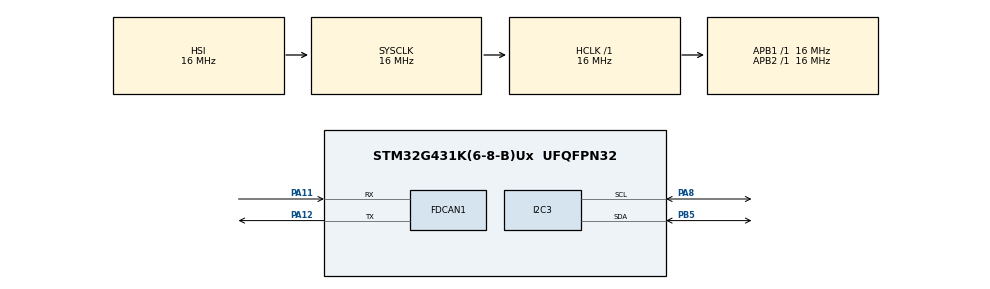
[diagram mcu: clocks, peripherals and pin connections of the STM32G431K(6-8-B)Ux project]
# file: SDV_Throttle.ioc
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FDCAN1.CalculateBaudRateNominal=500000
FDCAN1.CalculateTimeBitNominal=2000
FDCAN1.CalculateTimeQuantumNominal=125.0
FDCAN1.DataPrescaler=16
FDCAN1.DataTimeSeg1=14
FDCAN1.DataTimeSeg2=2
FDCAN1.NominalPrescaler=2
FDCAN1.NominalTimeSeg1=13
FREERTOS.Tasks01=defaultTask,24,128,StartDefaultTask,Default,NULL,Dynamic,NULL,NULL;canTask_tx,32,128,can_tx_task,Default,NULL,Dynamic,NULL,NULL;canTask_rx,33,128,can_rx_task,Default,NULL,Dynamic,NULL,NULL;canTask_panel,8,128,can_task_panel,Default,NULL,Dynamic,NULL,NULL;canTask_pot,8,128,can_task_pot,Default,NULL,Dynamic,NULL,NULL;canTask_lcd,8,128,can_task_lcd,Default,NULL,Dynamic,NULL,NULL
FREERTOS.configUSE_NEWLIB_REENTRANT=1
Mcu.Family=STM32G4
Mcu.Name=STM32G431K(6-8-B)Ux
Mcu.Package=UFQFPN32
NVIC.PriorityGroup=NVIC_PRIORITYGROUP_4
PA11.Mode=FDCAN_Activate
PA11.Signal=FDCAN1_RX
PA12.Mode=FDCAN_Activate
PA12.Signal=FDCAN1_TX
PA8.Mode=I2C
PA8.Signal=I2C3_SCL
PB5.Mode=I2C
PB5.Signal=I2C3_SDA
ProjectManager.HeapSize=0x200
ProjectManager.StackSize=0x400
ProjectManager.TargetToolchain=STM32CubeIDE
RCC.AHBFreq_Value=16000000
RCC.APB1Freq_Value=16000000
RCC.APB1TimFreq_Value=16000000
RCC.APB2Freq_Value=16000000
RCC.APB2TimFreq_Value=16000000
RCC.CortexFreq_Value=16000000
RCC.EXTERNAL_CLOCK_VALUE=12288000
RCC.HCLKFreq_Value=16000000
RCC.HSE_VALUE=8000000
RCC.HSI48_VALUE=48000000
RCC.HSI_VALUE=16000000
RCC.LSE_VALUE=32768
RCC.SYSCLKFreq_VALUE=16000000
RCC.USBFreq_Value=64000000
RCC.VCOOutputFreq_Value=128000000
VP_FREERTOS_VS_CMSIS_V2.Mode=CMSIS_V2
board=custom

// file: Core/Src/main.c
/* USER CODE BEGIN Header */
/**
  ******************************************************************************
  * @file           : main.c
  * @brief          : Main program body
  ******************************************************************************
  * @attention
  *
  * Copyright (c) 2022 STMicroelectronics.
  * All rights reserved.
  *
  * This software is licensed under terms that can be found in the LICENSE file
  * in the root directory of this software component.
  * If no LICENSE file comes with this software, it is provided AS-IS.
  *
  ******************************************************************************
  */
/* USER CODE END Header */
#include "main.h"
#include "cmsis_os.h"

FDCAN_HandleTypeDef hfdcan1;

I2C_HandleTypeDef hi2c3;

/* Definitions for defaultTask */
osThreadId_t defaultTaskHandle;
const osThreadAttr_t defaultTask_attributes = {
  .name = "defaultTask",
  .priority = (osPriority_t) osPriorityNormal,
  .stack_size = 128 * 4
};
/* Definitions for canTask_tx */
osThreadId_t canTask_txHandle;
const osThreadAttr_t canTask_tx_attributes = {
  .name = "canTask_tx",
  .priority = (osPriority_t) osPriorityAboveNormal,
  .stack_size = 128 * 4
};
/* Definitions for canTask_rx */
osThreadId_t canTask_rxHandle;
const osThreadAttr_t canTask_rx_attributes = {
  .name = "canTask_rx",
  .priority = (osPriority_t) osPriorityAboveNormal1,
  .stack_size = 128 * 4
};
/* Definitions for canTask_panel */
osThreadId_t canTask_panelHandle;
const osThreadAttr_t canTask_panel_attributes = {
  .name = "canTask_panel",
  .priority = (osPriority_t) osPriorityLow,
  .stack_size = 128 * 4
};
/* Definitions for canTask_pot */
osThreadId_t canTask_potHandle;
const osThreadAttr_t canTask_pot_attributes = {
  .name = "canTask_pot",
  .priority = (osPriority_t) osPriorityLow,
  .stack_size = 128 * 4
};
/* Definitions for canTask_lcd */
osThreadId_t canTask_lcdHandle;
const osThreadAttr_t canTask_lcd_attributes = {
  .name = "canTask_lcd",
  .priority = (osPriority_t) osPriorityLow,
  .stack_size = 128 * 4
};

void SystemClock_Config(void);
static void MX_GPIO_Init(void);
static void MX_FDCAN1_Init(void);
static void MX_I2C3_Init(void);
void StartDefaultTask(void *argument);
void can_tx_task(void *argument);
void can_rx_task(void *argument);
void can_task_panel(void *argument);
void can_task_pot(void *argument);
void can_task_lcd(void *argument);

int main(void)
{

  /* MCU Configuration--------------------------------------------------------*/

  /* Reset of all peripherals, Initializes the Flash interface and the Systick. */
  HAL_Init();

  /* Configure the system clock */
  SystemClock_Config();

  /* Initialize all configured peripherals */
  MX_GPIO_Init();
  MX_FDCAN1_Init();
  MX_I2C3_Init();
  /* USER CODE BEGIN 2 */

  can_init();
  //pot_init();
  //lcd_init();
  /* Init scheduler */
  osKernelInitialize();

  /* USER CODE END 2 */

  /* Init scheduler */
  osKernelInitialize();

  /* Create the thread(s) */
  /* creation of defaultTask */
  defaultTaskHandle = osThreadNew(StartDefaultTask, NULL, &defaultTask_attributes);

  /* creation of canTask_tx */
  //canTask_txHandle = osThreadNew(can_tx_task, NULL, &canTask_tx_attributes);

  /* creation of canTask_rx */
  //canTask_rxHandle = osThreadNew(can_rx_task, NULL, &canTask_rx_attributes);

  /* creation of canTask_panel */
  //canTask_panelHandle = osThreadNew(can_task_panel, NULL, &canTask_panel_attributes);

  /* creation of canTask_pot */
  canTask_potHandle = osThreadNew(can_task_pot, NULL, &canTask_pot_attributes);

  /* creation of canTask_lcd */
  //canTask_lcdHandle = osThreadNew(can_task_lcd, NULL, &canTask_lcd_attributes);

  /* Start scheduler */
  osKernelStart();

  /* We should never get here as control is now taken by the scheduler */
  /* Infinite loop */
  while (1)
  {

  }
}

void SystemClock_Config(void)
{
  RCC_OscInitTypeDef RCC_OscInitStruct = {0};
  RCC_ClkInitTypeDef RCC_ClkInitStruct = {0};

  /** Configure the main internal regulator output voltage
  */
  HAL_PWREx_ControlVoltageScaling(PWR_REGULATOR_VOLTAGE_SCALE1);

  /** Initializes the RCC Oscillators according to the specified parameters
  * in the RCC_OscInitTypeDef structure.
  */
  RCC_OscInitStruct.OscillatorType = RCC_OSCILLATORTYPE_HSI;
  RCC_OscInitStruct.HSIState = RCC_HSI_ON;
  RCC_OscInitStruct.HSICalibrationValue = RCC_HSICALIBRATION_DEFAULT;
  RCC_OscInitStruct.PLL.PLLState = RCC_PLL_NONE;
  if (HAL_RCC_OscConfig(&RCC_OscInitStruct) != HAL_OK)
  {
    Error_Handler();
  }

  /** Initializes the CPU, AHB and APB buses clocks
  */
  RCC_ClkInitStruct.ClockType = RCC_CLOCKTYPE_HCLK|RCC_CLOCKTYPE_SYSCLK
                              |RCC_CLOCKTYPE_PCLK1|RCC_CLOCKTYPE_PCLK2;
  RCC_ClkInitStruct.SYSCLKSource = RCC_SYSCLKSOURCE_HSI;
  RCC_ClkInitStruct.AHBCLKDivider = RCC_SYSCLK_DIV1;
  RCC_ClkInitStruct.APB1CLKDivider = RCC_HCLK_DIV1;
  RCC_ClkInitStruct.APB2CLKDivider = RCC_HCLK_DIV1;

  if (HAL_RCC_ClockConfig(&RCC_ClkInitStruct, FLASH_LATENCY_0) != HAL_OK)
  {
    Error_Handler();
  }
}

static void MX_FDCAN1_Init(void)
{

  hfdcan1.Instance = FDCAN1;
  hfdcan1.Init.ClockDivider = FDCAN_CLOCK_DIV1;
  hfdcan1.Init.FrameFormat = FDCAN_FRAME_CLASSIC;
  hfdcan1.Init.Mode = FDCAN_MODE_NORMAL;
  hfdcan1.Init.AutoRetransmission = DISABLE;
  hfdcan1.Init.TransmitPause = DISABLE;
  hfdcan1.Init.ProtocolException = DISABLE;
  hfdcan1.Init.NominalPrescaler = 2;
  hfdcan1.Init.NominalSyncJumpWidth = 1;
  hfdcan1.Init.NominalTimeSeg1 = 13;
  hfdcan1.Init.NominalTimeSeg2 = 2;
  hfdcan1.Init.DataPrescaler = 16;
  hfdcan1.Init.DataSyncJumpWidth = 1;
  hfdcan1.Init.DataTimeSeg1 = 14;
  hfdcan1.Init.DataTimeSeg2 = 2;
  hfdcan1.Init.StdFiltersNbr = 0;
  hfdcan1.Init.ExtFiltersNbr = 0;
  hfdcan1.Init.TxFifoQueueMode = FDCAN_TX_FIFO_OPERATION;
  if (HAL_FDCAN_Init(&hfdcan1) != HAL_OK)
  {
    Error_Handler();
  }

}

static void MX_I2C3_Init(void)
{

  hi2c3.Instance = I2C3;
  hi2c3.Init.Timing = 0x00303D5B;
  hi2c3.Init.OwnAddress1 = 0;
  hi2c3.Init.AddressingMode = I2C_ADDRESSINGMODE_7BIT;
  hi2c3.Init.DualAddressMode = I2C_DUALADDRESS_DISABLE;
  hi2c3.Init.OwnAddress2 = 0;
  hi2c3.Init.OwnAddress2Masks = I2C_OA2_NOMASK;
  hi2c3.Init.GeneralCallMode = I2C_GENERALCALL_DISABLE;
  hi2c3.Init.NoStretchMode = I2C_NOSTRETCH_DISABLE;
  if (HAL_I2C_Init(&hi2c3) != HAL_OK)
  {
    Error_Handler();
  }

  /** Configure Analogue filter
  */
  if (HAL_I2CEx_ConfigAnalogFilter(&hi2c3, I2C_ANALOGFILTER_ENABLE) != HAL_OK)
  {
    Error_Handler();
  }

  /** Configure Digital filter
  */
  if (HAL_I2CEx_ConfigDigitalFilter(&hi2c3, 0) != HAL_OK)
  {
    Error_Handler();
  }

}

static void MX_GPIO_Init(void)
{

  /* GPIO Ports Clock Enable */
  __HAL_RCC_GPIOA_CLK_ENABLE();
  __HAL_RCC_GPIOB_CLK_ENABLE();

}

void StartDefaultTask(void *argument)
{
  for(;;)
  {
    osDelay(1);
  }
}

void Error_Handler(void)
{
  __disable_irq();
  while (1)
  {
  }
}
